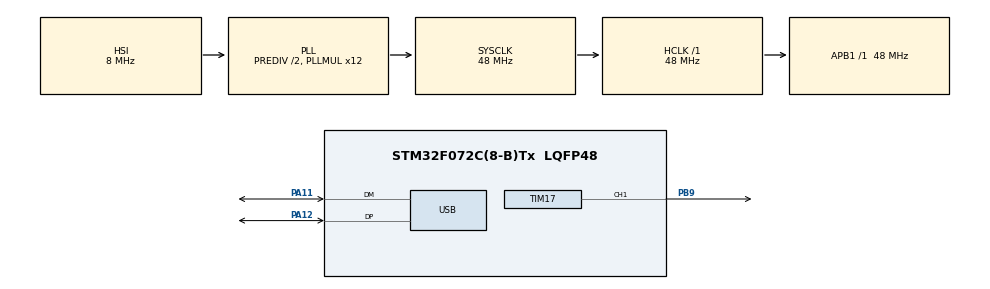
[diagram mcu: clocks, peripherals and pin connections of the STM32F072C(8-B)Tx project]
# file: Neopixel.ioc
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Dma.Request0=TIM17_CH1/UP
Dma.TIM17_CH1/UP.0.Direction=DMA_MEMORY_TO_PERIPH
Dma.TIM17_CH1/UP.0.Instance=DMA1_Channel1
Dma.TIM17_CH1/UP.0.MemDataAlignment=DMA_MDATAALIGN_HALFWORD
Dma.TIM17_CH1/UP.0.MemInc=DMA_MINC_ENABLE
Dma.TIM17_CH1/UP.0.Mode=DMA_CIRCULAR
Dma.TIM17_CH1/UP.0.PeriphDataAlignment=DMA_PDATAALIGN_HALFWORD
Dma.TIM17_CH1/UP.0.PeriphInc=DMA_PINC_DISABLE
Dma.TIM17_CH1/UP.0.Priority=DMA_PRIORITY_LOW
Mcu.Family=STM32F0
Mcu.Name=STM32F072C(8-B)Tx
Mcu.Package=LQFP48
Mcu.UserConstants=LED_CNT,60
NVIC.DMA1_Channel1_IRQn=true\:0\:0\:false\:false\:true\:false\:true\:true
PA11.Mode=Device
PA11.Signal=USB_DM
PA12.Mode=Device
PA12.Signal=USB_DP
PA13.Mode=Serial_Wire
PA13.Signal=SYS_SWDIO
PA14.Mode=Serial_Wire
PA14.Signal=SYS_SWCLK
PB9.Signal=S_TIM17_CH1
ProjectManager.HeapSize=0x200
ProjectManager.StackSize=0x400
ProjectManager.TargetToolchain=CMake
RCC.AHBFreq_Value=48000000
RCC.APB1Freq_Value=48000000
RCC.APB1TimFreq_Value=48000000
RCC.HCLKFreq_Value=48000000
RCC.PLLDivider=RCC_PREDIV_DIV2
RCC.PLLMUL=RCC_PLL_MUL12
RCC.SYSCLKFreq_VALUE=48000000
RCC.SYSCLKSource=RCC_SYSCLKSOURCE_PLLCLK
SH.S_TIM17_CH1.0=TIM17_CH1,PWM Generation1 CH1
TIM17.Channel=TIM_CHANNEL_1
TIM17.Period=LED_CNT -1 
VP_TIM17_VS_ClockSourceINT.Mode=Enable_Timer
board=custom

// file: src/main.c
/* USER CODE BEGIN Header */
/**
 ******************************************************************************
 * @file           : main.c
 * @brief          : Main program body
 ******************************************************************************
 * @attention
 *
 * Copyright (c) 2026 STMicroelectronics.
 * All rights reserved.
 *
 * This software is licensed under terms that can be found in the LICENSE file
 * in the root directory of this software component.
 * If no LICENSE file comes with this software, it is provided AS-IS.
 *
 ******************************************************************************
 */
/* USER CODE END Header */
#include "main.h"

/* USER CODE BEGIN Includes */
#include "stm32f0xx_hal_tim.h"
#include <string.h>
/* USER CODE END Includes */

TIM_HandleTypeDef htim17;
DMA_HandleTypeDef hdma_tim17_ch1_up;

PCD_HandleTypeDef hpcd_USB_FS;

void SystemClock_Config(void);
static void MX_GPIO_Init(void);
static void MX_DMA_Init(void);
static void MX_TIM17_Init(void);
static void MX_USB_PCD_Init(void);

/* USER CODE BEGIN 0 */

// void HAL_TIM_PWM_PulseFinishedCallback(TIM_HandleTypeDef *htim){
//   HAL_TIM_PWM_Stop_DMA(htim, TIM_CHANNEL_1);
// }

uint16_t pwmData[24+100];

void sendColor(uint8_t red, uint8_t green, uint8_t blue)
{

  uint32_t color = ((uint32_t)green << 16) | ((uint32_t)red << 8) | blue; // GRB, MSB en premier

  for (int i = 0; i < 24; i++)
  {
    if (color & (1 << (23 - i))){
      pwmData[i] = 2/3.0 * LED_CNT; // bit 1
    }
    else
    {
      pwmData[i] = 1/3.0 * LED_CNT; // bit 0
    }
  }

  HAL_TIM_PWM_Start_DMA(&htim17, TIM_CHANNEL_1, (uint32_t*)pwmData, sizeof(pwmData) / sizeof(pwmData[0]));

}

/* USER CODE END 0 */

int main(void)
{

  /* MCU Configuration--------------------------------------------------------*/

  /* Reset of all peripherals, Initializes the Flash interface and the Systick. */
  HAL_Init();

  /* Configure the system clock */
  SystemClock_Config();

  /* Initialize all configured peripherals */
  MX_GPIO_Init();
  MX_DMA_Init();
  MX_TIM17_Init();
  MX_USB_PCD_Init();
  /* USER CODE BEGIN 2 */

  memset(pwmData, 0, sizeof(pwmData));
  sendColor(0,0,255);

  /* USER CODE END 2 */

  /* Infinite loop */
  /* USER CODE BEGIN WHILE */
  while (1)
  {
    for(int red = 0; red < 256; red++){
      sendColor(red, 0, 0);
      HAL_Delay(2000/256);
    }

    /* USER CODE END WHILE */

  }
}

void SystemClock_Config(void)
{
  RCC_OscInitTypeDef RCC_OscInitStruct = {0};
  RCC_ClkInitTypeDef RCC_ClkInitStruct = {0};
  RCC_PeriphCLKInitTypeDef PeriphClkInit = {0};

  /** Initializes the RCC Oscillators according to the specified parameters
  * in the RCC_OscInitTypeDef structure.
  */
  RCC_OscInitStruct.OscillatorType = RCC_OSCILLATORTYPE_HSI|RCC_OSCILLATORTYPE_HSI48;
  RCC_OscInitStruct.HSIState = RCC_HSI_ON;
  RCC_OscInitStruct.HSI48State = RCC_HSI48_ON;
  RCC_OscInitStruct.HSICalibrationValue = RCC_HSICALIBRATION_DEFAULT;
  RCC_OscInitStruct.PLL.PLLState = RCC_PLL_ON;
  RCC_OscInitStruct.PLL.PLLSource = RCC_PLLSOURCE_HSI;
  RCC_OscInitStruct.PLL.PLLMUL = RCC_PLL_MUL12;
  RCC_OscInitStruct.PLL.PREDIV = RCC_PREDIV_DIV2;
  if (HAL_RCC_OscConfig(&RCC_OscInitStruct) != HAL_OK)
  {
    Error_Handler();
  }

  /** Initializes the CPU, AHB and APB buses clocks
  */
  RCC_ClkInitStruct.ClockType = RCC_CLOCKTYPE_HCLK|RCC_CLOCKTYPE_SYSCLK
                              |RCC_CLOCKTYPE_PCLK1;
  RCC_ClkInitStruct.SYSCLKSource = RCC_SYSCLKSOURCE_PLLCLK;
  RCC_ClkInitStruct.AHBCLKDivider = RCC_SYSCLK_DIV1;
  RCC_ClkInitStruct.APB1CLKDivider = RCC_HCLK_DIV1;

  if (HAL_RCC_ClockConfig(&RCC_ClkInitStruct, FLASH_LATENCY_1) != HAL_OK)
  {
    Error_Handler();
  }
  PeriphClkInit.PeriphClockSelection = RCC_PERIPHCLK_USB;
  PeriphClkInit.UsbClockSelection = RCC_USBCLKSOURCE_HSI48;

  if (HAL_RCCEx_PeriphCLKConfig(&PeriphClkInit) != HAL_OK)
  {
    Error_Handler();
  }
}

static void MX_TIM17_Init(void)
{

  TIM_OC_InitTypeDef sConfigOC = {0};
  TIM_BreakDeadTimeConfigTypeDef sBreakDeadTimeConfig = {0};

  htim17.Instance = TIM17;
  htim17.Init.Prescaler = 0;
  htim17.Init.CounterMode = TIM_COUNTERMODE_UP;
  htim17.Init.Period = LED_CNT -1 ;
  htim17.Init.ClockDivision = TIM_CLOCKDIVISION_DIV1;
  htim17.Init.RepetitionCounter = 0;
  htim17.Init.AutoReloadPreload = TIM_AUTORELOAD_PRELOAD_DISABLE;
  if (HAL_TIM_Base_Init(&htim17) != HAL_OK)
  {
    Error_Handler();
  }
  if (HAL_TIM_PWM_Init(&htim17) != HAL_OK)
  {
    Error_Handler();
  }
  sConfigOC.OCMode = TIM_OCMODE_PWM1;
  sConfigOC.Pulse = 0;
  sConfigOC.OCPolarity = TIM_OCPOLARITY_HIGH;
  sConfigOC.OCNPolarity = TIM_OCNPOLARITY_HIGH;
  sConfigOC.OCFastMode = TIM_OCFAST_DISABLE;
  sConfigOC.OCIdleState = TIM_OCIDLESTATE_RESET;
  sConfigOC.OCNIdleState = TIM_OCNIDLESTATE_RESET;
  if (HAL_TIM_PWM_ConfigChannel(&htim17, &sConfigOC, TIM_CHANNEL_1) != HAL_OK)
  {
    Error_Handler();
  }
  sBreakDeadTimeConfig.OffStateRunMode = TIM_OSSR_DISABLE;
  sBreakDeadTimeConfig.OffStateIDLEMode = TIM_OSSI_DISABLE;
  sBreakDeadTimeConfig.LockLevel = TIM_LOCKLEVEL_OFF;
  sBreakDeadTimeConfig.DeadTime = 0;
  sBreakDeadTimeConfig.BreakState = TIM_BREAK_DISABLE;
  sBreakDeadTimeConfig.BreakPolarity = TIM_BREAKPOLARITY_HIGH;
  sBreakDeadTimeConfig.AutomaticOutput = TIM_AUTOMATICOUTPUT_DISABLE;
  if (HAL_TIMEx_ConfigBreakDeadTime(&htim17, &sBreakDeadTimeConfig) != HAL_OK)
  {
    Error_Handler();
  }
  HAL_TIM_MspPostInit(&htim17);

}

static void MX_USB_PCD_Init(void)
{

  hpcd_USB_FS.Instance = USB;
  hpcd_USB_FS.Init.dev_endpoints = 8;
  hpcd_USB_FS.Init.speed = PCD_SPEED_FULL;
  hpcd_USB_FS.Init.phy_itface = PCD_PHY_EMBEDDED;
  hpcd_USB_FS.Init.low_power_enable = DISABLE;
  hpcd_USB_FS.Init.lpm_enable = DISABLE;
  hpcd_USB_FS.Init.battery_charging_enable = DISABLE;
  if (HAL_PCD_Init(&hpcd_USB_FS) != HAL_OK)
  {
    Error_Handler();
  }

}

static void MX_DMA_Init(void)
{

  /* DMA controller clock enable */
  __HAL_RCC_DMA1_CLK_ENABLE();

  /* DMA interrupt init */
  /* DMA1_Channel1_IRQn interrupt configuration */
  HAL_NVIC_SetPriority(DMA1_Channel1_IRQn, 0, 0);
  HAL_NVIC_EnableIRQ(DMA1_Channel1_IRQn);

}

static void MX_GPIO_Init(void)
{

  /* GPIO Ports Clock Enable */
  __HAL_RCC_GPIOA_CLK_ENABLE();
  __HAL_RCC_GPIOB_CLK_ENABLE();

}

void Error_Handler(void)
{
  __disable_irq();
  while (1)
  {
  }
}
